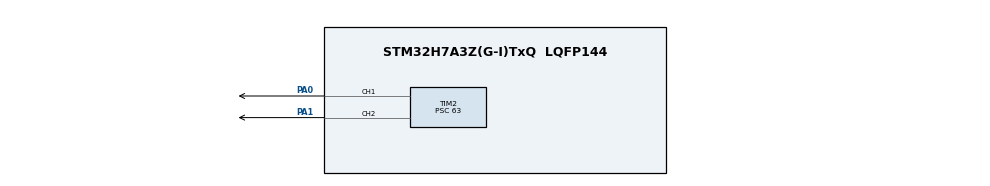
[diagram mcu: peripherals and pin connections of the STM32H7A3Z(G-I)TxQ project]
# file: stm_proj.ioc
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CORTEX_M7.default_mode_Activation=1
FREERTOS.Tasks01=defaultTask,24,128,StartDefaultTask,Default,NULL,Dynamic,NULL,NULL;Task_10ms,32,128,runTask10ms,Default,NULL,Dynamic,NULL,NULL;Task_20ms,24,128,runTask20ms,Default,NULL,Dynamic,NULL,NULL;Task_50ms,24,128,runTask50ms,Default,NULL,Dynamic,NULL,NULL;Initialization,48,128,runInit,Default,NULL,Dynamic,NULL,NULL;Task_1ms,40,128,runTask1ms,Default,NULL,Dynamic,NULL,NULL
FREERTOS.configUSE_NEWLIB_REENTRANT=1
Mcu.Family=STM32H7
Mcu.Name=STM32H7A3Z(G-I)TxQ
Mcu.Package=LQFP144
NUCLEO-H7A3ZI-Q.BUTTON=1
NUCLEO-H7A3ZI-Q.Bsp_Common_DEMO=true
NUCLEO-H7A3ZI-Q.LD1=true
NUCLEO-H7A3ZI-Q.LD2=true
NUCLEO-H7A3ZI-Q.LD3=true
NUCLEO-H7A3ZI-Q.VCP=true
NVIC.EXTI15_10_IRQn=true\:5\:0\:false\:false\:true\:true\:false\:true\:true
NVIC.PriorityGroup=NVIC_PRIORITYGROUP_4
NVIC.TIM1_UP_IRQn=true\:15\:0\:false\:false\:true\:false\:false\:true\:true
NVIC.TimeBase=TIM1_UP_IRQn
NVIC.TimeBaseIP=TIM1
PA0.Signal=S_TIM2_CH1_ETR
PA1.Signal=S_TIM2_CH2
PB0.Signal=S_TIM3_CH3
PB14.Signal=TIM8_CH2N
PC14-OSC32_IN.GPIO_Label=OSC32_IN
PC14-OSC32_IN.Signal=RCC_OSC32_IN
PC15-OSC32_OUT.GPIO_Label=OSC32_OUT
PC15-OSC32_OUT.Signal=RCC_OSC32_OUT
PD8.Signal=USART3_TX
PD9.Signal=USART3_RX
PH0-OSC_IN.GPIO_Label=PH0-MCU
PH0-OSC_IN.Signal=RCC_OSC_IN
PH1-OSC_OUT.GPIO_Label=PH1-MCU
PH1-OSC_OUT.Signal=RCC_OSC_OUT
ProjectManager.HeapSize=0x200
ProjectManager.StackSize=0x400
ProjectManager.TargetToolchain=STM32CubeIDE
RCC.ADCFreq_Value=129000000
RCC.APB1Freq_Value=64000000
RCC.APB2Freq_Value=64000000
RCC.APB3Freq_Value=64000000
RCC.APB4Freq_Value=64000000
RCC.CortexFreq_Value=64000000
RCC.DIVM1=4
RCC.DIVM3=1
RCC.DIVN1=8
RCC.DIVN3=24
RCC.DIVQ1=4
RCC.HCLKFreq_Value=64000000
RCC.HSE_VALUE=8000000
RCC.PLLFRACN=0
RCC.PWR_Regulator_Voltage_Scale=PWR_REGULATOR_VOLTAGE_SCALE0
RCC.SYSCLKFreq_VALUE=64000000
RCC.SYSCLKSource=RCC_SYSCLKSOURCE_PLLCLK
RCC.SupplySource=PWR_DIRECT_SMPS_SUPPLY
RCC.USBCLockSelection=RCC_USBCLKSOURCE_HSI48
RCC.USBFreq_Value=48000000
SH.S_TIM2_CH1_ETR.0=TIM2_CH1,PWM Generation1 CH1
SH.S_TIM2_CH2.0=TIM2_CH2,PWM Generation2 CH2
SH.S_TIM3_CH3.0=TIM3_CH3
TIM2.AutoReloadPreload=TIM_AUTORELOAD_PRELOAD_ENABLE
TIM2.Channel-PWM\ Generation1\ CH1=TIM_CHANNEL_1
TIM2.Channel-PWM\ Generation2\ CH2=TIM_CHANNEL_2
TIM2.Period=999
TIM2.Prescaler=63
TIM3.AutoReloadPreload=TIM_AUTORELOAD_PRELOAD_ENABLE
TIM3.Period=999
TIM3.Prescaler=63
TIM8.AutoReloadPreload=TIM_AUTORELOAD_PRELOAD_ENABLE
TIM8.Period=999
TIM8.Prescaler=63
VP_FREERTOS_VS_CMSIS_V2.Mode=CMSIS_V2
VP_MEMORYMAP_VS_MEMORYMAP.Mode=CurAppReg
VP_NUCLEO-H7A3ZI-Q_VS_BSP_COMMON.Mode=COMMON
VP_SYS_VS_tim1.Mode=TIM1
VP_TIM2_VS_ClockSourceINT.Mode=Internal
VP_TIM3_VS_ClockSourceINT.Mode=Internal
VP_TIM8_VS_ClockSourceINT.Mode=Internal
board=NUCLEO-H7A3ZI-Q

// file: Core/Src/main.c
/* USER CODE BEGIN Header */
/**
  ******************************************************************************
  * @file           : main.c
  * @brief          : Main program body
  ******************************************************************************
  * @attention
  *
  * Copyright (c) 2026 STMicroelectronics.
  * All rights reserved.
  *
  * This software is licensed under terms that can be found in the LICENSE file
  * in the root directory of this software component.
  * If no LICENSE file comes with this software, it is provided AS-IS.
  *
  ******************************************************************************
  */
/* USER CODE END Header */
#include "main.h"
#include "FreeRTOS.h"
#include "cmsis_os2.h"

COM_InitTypeDef BspCOMInit;
__IO uint32_t BspButtonState = BUTTON_RELEASED;

TIM_HandleTypeDef htim2;
TIM_HandleTypeDef htim3;
TIM_HandleTypeDef htim8;

/* Definitions for defaultTask */
osThreadId_t defaultTaskHandle;
const osThreadAttr_t defaultTask_attributes = {
  .name = "defaultTask",
  .stack_size = 128 * 4,
  .priority = (osPriority_t) osPriorityNormal,
};
/* Definitions for Task_10ms */
osThreadId_t Task_10msHandle;
const osThreadAttr_t Task_10ms_attributes = {
  .name = "Task_10ms",
  .stack_size = 128 * 4,
  .priority = (osPriority_t) osPriorityAboveNormal,
};
/* Definitions for Task_20ms */
osThreadId_t Task_20msHandle;
const osThreadAttr_t Task_20ms_attributes = {
  .name = "Task_20ms",
  .stack_size = 128 * 4,
  .priority = (osPriority_t) osPriorityNormal,
};
/* Definitions for Task_50ms */
osThreadId_t Task_50msHandle;
const osThreadAttr_t Task_50ms_attributes = {
  .name = "Task_50ms",
  .stack_size = 128 * 4,
  .priority = (osPriority_t) osPriorityNormal,
};
/* Definitions for Initialization */
osThreadId_t InitializationHandle;
const osThreadAttr_t Initialization_attributes = {
  .name = "Initialization",
  .stack_size = 128 * 4,
  .priority = (osPriority_t) osPriorityRealtime,
};
/* Definitions for Task_1ms */
osThreadId_t Task_1msHandle;
const osThreadAttr_t Task_1ms_attributes = {
  .name = "Task_1ms",
  .stack_size = 128 * 4,
  .priority = (osPriority_t) osPriorityHigh,
};

void SystemClock_Config(void);
static void MPU_Config(void);
static void MX_GPIO_Init(void);
static void MX_TIM2_Init(void);
static void MX_TIM3_Init(void);
static void MX_TIM8_Init(void);
void StartDefaultTask(void *argument);
void runTask10ms(void *argument);
void runTask20ms(void *argument);
void runTask50ms(void *argument);
void runInit(void *argument);
void runTask1ms(void *argument);

int main(void)
{

  /* MPU Configuration--------------------------------------------------------*/
  MPU_Config();

  /* MCU Configuration--------------------------------------------------------*/

  /* Reset of all peripherals, Initializes the Flash interface and the Systick. */
  HAL_Init();

  /* Configure the system clock */
  SystemClock_Config();

  /* Initialize all configured peripherals */
  MX_GPIO_Init();
  MX_TIM2_Init();
  MX_TIM3_Init();
  MX_TIM8_Init();

  /* Init scheduler */
  osKernelInitialize();

  /* Create the thread(s) */
  /* creation of defaultTask */
  defaultTaskHandle = osThreadNew(StartDefaultTask, NULL, &defaultTask_attributes);

  /* creation of Task_10ms */
  Task_10msHandle = osThreadNew(runTask10ms, NULL, &Task_10ms_attributes);

  /* creation of Task_20ms */
  Task_20msHandle = osThreadNew(runTask20ms, NULL, &Task_20ms_attributes);

  /* creation of Task_50ms */
  Task_50msHandle = osThreadNew(runTask50ms, NULL, &Task_50ms_attributes);

  /* creation of Initialization */
  InitializationHandle = osThreadNew(runInit, NULL, &Initialization_attributes);

  /* creation of Task_1ms */
  Task_1msHandle = osThreadNew(runTask1ms, NULL, &Task_1ms_attributes);

  /* Initialize leds */
  BSP_LED_Init(LED_GREEN);
  BSP_LED_Init(LED_YELLOW);
  BSP_LED_Init(LED_RED);

  /* Initialize USER push-button, will be used to trigger an interrupt each time it's pressed.*/
  BSP_PB_Init(BUTTON_USER, BUTTON_MODE_EXTI);

  /* Initialize COM1 port (115200, 8 bits (7-bit data + 1 stop bit), no parity */
  BspCOMInit.BaudRate   = 115200;
  BspCOMInit.WordLength = COM_WORDLENGTH_8B;
  BspCOMInit.StopBits   = COM_STOPBITS_1;
  BspCOMInit.Parity     = COM_PARITY_NONE;
  BspCOMInit.HwFlowCtl  = COM_HWCONTROL_NONE;
  if (BSP_COM_Init(COM1, &BspCOMInit) != BSP_ERROR_NONE)
  {
    Error_Handler();
  }

  /* USER CODE BEGIN BSP */

  /* -- Sample board code to send message over COM1 port ---- */
  printf("Welcome to STM32 world !\n\r");

  /* -- Sample board code to switch on leds ---- */
//  BSP_LED_On(LED_GREEN);
//  BSP_LED_On(LED_YELLOW);
//  BSP_LED_On(LED_RED);

  /* USER CODE END BSP */

  /* Start scheduler */
  osKernelStart();

  /* We should never get here as control is now taken by the scheduler */

  /* Infinite loop */
  /* USER CODE BEGIN WHILE */
  while (1)
  {

    /* -- Sample board code for User push-button in interrupt mode ---- */
//    if (BspButtonState == BUTTON_PRESSED)
//    {
//      /* Update button state */
//      BspButtonState = BUTTON_RELEASED;
//      /* -- Sample board code to toggle leds ---- */
//      BSP_LED_Toggle(LED_GREEN);
//      BSP_LED_Toggle(LED_YELLOW);
//      BSP_LED_Toggle(LED_RED);

      /* ..... Perform your action ..... */
//    }
    /* USER CODE END WHILE */

  }
}

void SystemClock_Config(void)
{
  RCC_OscInitTypeDef RCC_OscInitStruct = {0};
  RCC_ClkInitTypeDef RCC_ClkInitStruct = {0};

  /*AXI clock gating */
  RCC->CKGAENR = 0xE003FFFF;

  /** Supply configuration update enable
  */
  HAL_PWREx_ConfigSupply(PWR_DIRECT_SMPS_SUPPLY);

  /** Configure the main internal regulator output voltage
  */
  __HAL_PWR_VOLTAGESCALING_CONFIG(PWR_REGULATOR_VOLTAGE_SCALE0);

  while(!__HAL_PWR_GET_FLAG(PWR_FLAG_VOSRDY)) {}

  /** Initializes the RCC Oscillators according to the specified parameters
  * in the RCC_OscInitTypeDef structure.
  */
  RCC_OscInitStruct.OscillatorType = RCC_OSCILLATORTYPE_HSI;
  RCC_OscInitStruct.HSIState = RCC_HSI_DIV1;
  RCC_OscInitStruct.HSICalibrationValue = 64;
  RCC_OscInitStruct.PLL.PLLState = RCC_PLL_ON;
  RCC_OscInitStruct.PLL.PLLSource = RCC_PLLSOURCE_HSI;
  RCC_OscInitStruct.PLL.PLLM = 4;
  RCC_OscInitStruct.PLL.PLLN = 8;
  RCC_OscInitStruct.PLL.PLLP = 2;
  RCC_OscInitStruct.PLL.PLLQ = 4;
  RCC_OscInitStruct.PLL.PLLR = 2;
  RCC_OscInitStruct.PLL.PLLRGE = RCC_PLL1VCIRANGE_3;
  RCC_OscInitStruct.PLL.PLLVCOSEL = RCC_PLL1VCOWIDE;
  RCC_OscInitStruct.PLL.PLLFRACN = 0;
  if (HAL_RCC_OscConfig(&RCC_OscInitStruct) != HAL_OK)
  {
    Error_Handler();
  }

  /** Initializes the CPU, AHB and APB buses clocks
  */
  RCC_ClkInitStruct.ClockType = RCC_CLOCKTYPE_HCLK|RCC_CLOCKTYPE_SYSCLK
                              |RCC_CLOCKTYPE_PCLK1|RCC_CLOCKTYPE_PCLK2
                              |RCC_CLOCKTYPE_D3PCLK1|RCC_CLOCKTYPE_D1PCLK1;
  RCC_ClkInitStruct.SYSCLKSource = RCC_SYSCLKSOURCE_PLLCLK;
  RCC_ClkInitStruct.SYSCLKDivider = RCC_SYSCLK_DIV1;
  RCC_ClkInitStruct.AHBCLKDivider = RCC_HCLK_DIV1;
  RCC_ClkInitStruct.APB3CLKDivider = RCC_APB3_DIV1;
  RCC_ClkInitStruct.APB1CLKDivider = RCC_APB1_DIV1;
  RCC_ClkInitStruct.APB2CLKDivider = RCC_APB2_DIV1;
  RCC_ClkInitStruct.APB4CLKDivider = RCC_APB4_DIV1;

  if (HAL_RCC_ClockConfig(&RCC_ClkInitStruct, FLASH_LATENCY_1) != HAL_OK)
  {
    Error_Handler();
  }
}

static void MX_TIM2_Init(void)
{

  TIM_ClockConfigTypeDef sClockSourceConfig = {0};
  TIM_MasterConfigTypeDef sMasterConfig = {0};
  TIM_OC_InitTypeDef sConfigOC = {0};

  htim2.Instance = TIM2;
  htim2.Init.Prescaler = 63;
  htim2.Init.CounterMode = TIM_COUNTERMODE_UP;
  htim2.Init.Period = 999;
  htim2.Init.ClockDivision = TIM_CLOCKDIVISION_DIV1;
  htim2.Init.AutoReloadPreload = TIM_AUTORELOAD_PRELOAD_ENABLE;
  if (HAL_TIM_Base_Init(&htim2) != HAL_OK)
  {
    Error_Handler();
  }
  sClockSourceConfig.ClockSource = TIM_CLOCKSOURCE_INTERNAL;
  if (HAL_TIM_ConfigClockSource(&htim2, &sClockSourceConfig) != HAL_OK)
  {
    Error_Handler();
  }
  if (HAL_TIM_PWM_Init(&htim2) != HAL_OK)
  {
    Error_Handler();
  }
  sMasterConfig.MasterOutputTrigger = TIM_TRGO_RESET;
  sMasterConfig.MasterSlaveMode = TIM_MASTERSLAVEMODE_DISABLE;
  if (HAL_TIMEx_MasterConfigSynchronization(&htim2, &sMasterConfig) != HAL_OK)
  {
    Error_Handler();
  }
  sConfigOC.OCMode = TIM_OCMODE_PWM1;
  sConfigOC.Pulse = 0;
  sConfigOC.OCPolarity = TIM_OCPOLARITY_HIGH;
  sConfigOC.OCFastMode = TIM_OCFAST_DISABLE;
  if (HAL_TIM_PWM_ConfigChannel(&htim2, &sConfigOC, TIM_CHANNEL_1) != HAL_OK)
  {
    Error_Handler();
  }
  if (HAL_TIM_PWM_ConfigChannel(&htim2, &sConfigOC, TIM_CHANNEL_2) != HAL_OK)
  {
    Error_Handler();
  }
  HAL_TIM_MspPostInit(&htim2);

}

static void MX_TIM3_Init(void)
{

  TIM_ClockConfigTypeDef sClockSourceConfig = {0};
  TIM_MasterConfigTypeDef sMasterConfig = {0};

  htim3.Instance = TIM3;
  htim3.Init.Prescaler = 63;
  htim3.Init.CounterMode = TIM_COUNTERMODE_UP;
  htim3.Init.Period = 999;
  htim3.Init.ClockDivision = TIM_CLOCKDIVISION_DIV1;
  htim3.Init.AutoReloadPreload = TIM_AUTORELOAD_PRELOAD_ENABLE;
  if (HAL_TIM_Base_Init(&htim3) != HAL_OK)
  {
    Error_Handler();
  }
  sClockSourceConfig.ClockSource = TIM_CLOCKSOURCE_INTERNAL;
  if (HAL_TIM_ConfigClockSource(&htim3, &sClockSourceConfig) != HAL_OK)
  {
    Error_Handler();
  }
  sMasterConfig.MasterOutputTrigger = TIM_TRGO_RESET;
  sMasterConfig.MasterSlaveMode = TIM_MASTERSLAVEMODE_DISABLE;
  if (HAL_TIMEx_MasterConfigSynchronization(&htim3, &sMasterConfig) != HAL_OK)
  {
    Error_Handler();
  }

}

static void MX_TIM8_Init(void)
{

  TIM_ClockConfigTypeDef sClockSourceConfig = {0};
  TIM_MasterConfigTypeDef sMasterConfig = {0};

  htim8.Instance = TIM8;
  htim8.Init.Prescaler = 63;
  htim8.Init.CounterMode = TIM_COUNTERMODE_UP;
  htim8.Init.Period = 999;
  htim8.Init.ClockDivision = TIM_CLOCKDIVISION_DIV1;
  htim8.Init.RepetitionCounter = 0;
  htim8.Init.AutoReloadPreload = TIM_AUTORELOAD_PRELOAD_ENABLE;
  if (HAL_TIM_Base_Init(&htim8) != HAL_OK)
  {
    Error_Handler();
  }
  sClockSourceConfig.ClockSource = TIM_CLOCKSOURCE_INTERNAL;
  if (HAL_TIM_ConfigClockSource(&htim8, &sClockSourceConfig) != HAL_OK)
  {
    Error_Handler();
  }
  sMasterConfig.MasterOutputTrigger = TIM_TRGO_RESET;
  sMasterConfig.MasterOutputTrigger2 = TIM_TRGO2_RESET;
  sMasterConfig.MasterSlaveMode = TIM_MASTERSLAVEMODE_DISABLE;
  if (HAL_TIMEx_MasterConfigSynchronization(&htim8, &sMasterConfig) != HAL_OK)
  {
    Error_Handler();
  }

}

static void MX_GPIO_Init(void)
{

  /* GPIO Ports Clock Enable */
  __HAL_RCC_GPIOC_CLK_ENABLE();
  __HAL_RCC_GPIOH_CLK_ENABLE();
  __HAL_RCC_GPIOA_CLK_ENABLE();
  __HAL_RCC_GPIOB_CLK_ENABLE();

}

void StartDefaultTask(void *argument)
{
  /* USER CODE BEGIN 5 */
	  HAL_TIM_PWM_Start(&htim3, TIM_CHANNEL_3);

	  // FORCE 100%
	  __HAL_TIM_SET_COMPARE(&htim3, TIM_CHANNEL_3, 999);
	// TIM3
//	HAL_GPIO_WritePin(GPIOB, GPIO_PIN_0, GPIO_PIN_SET);
    for(;;)
    {
      osDelay(1000);
    }
  /* USER CODE END 5 */
}

void runTask10ms(void *argument)
{
  /* USER CODE BEGIN runTask10ms */
  /* Infinite loop */
  for(;;)
  {
	  cyclic_task_10ms();
    osDelay(10);
  }
  /* USER CODE END runTask10ms */
}

void runTask20ms(void *argument)
{
  /* USER CODE BEGIN runTask20ms */
  /* Infinite loop */
  for(;;)
  {
	  cyclic_task_20ms();
    osDelay(20);
  }
  /* USER CODE END runTask20ms */
}

void runTask50ms(void *argument)
{
  /* USER CODE BEGIN runTask50ms */
  /* Infinite loop */
  for(;;)
  {
	  cyclic_task_50ms();
    osDelay(50);
  }
  /* USER CODE END runTask50ms */
}

void runInit(void *argument)
{
  /* USER CODE BEGIN runInit */
  /* Infinite loop */
  for(;;)
  {
	  init();
    osDelay(1);
  }
  /* USER CODE END runInit */
}

void runTask1ms(void *argument)
{
  /* USER CODE BEGIN runTask1ms */
  /* Infinite loop */
  for(;;)
  {
	  cyclic_task_1ms();
    osDelay(1);
  }
  /* USER CODE END runTask1ms */
}

 /* MPU Configuration */

void MPU_Config(void)
{
  MPU_Region_InitTypeDef MPU_InitStruct = {0};

  /* Disables the MPU */
  HAL_MPU_Disable();

  /** Initializes and configures the Region and the memory to be protected
  */
  MPU_InitStruct.Enable = MPU_REGION_ENABLE;
  MPU_InitStruct.Number = MPU_REGION_NUMBER0;
  MPU_InitStruct.BaseAddress = 0x0;
  MPU_InitStruct.Size = MPU_REGION_SIZE_4GB;
  MPU_InitStruct.SubRegionDisable = 0x87;
  MPU_InitStruct.TypeExtField = MPU_TEX_LEVEL0;
  MPU_InitStruct.AccessPermission = MPU_REGION_NO_ACCESS;
  MPU_InitStruct.DisableExec = MPU_INSTRUCTION_ACCESS_DISABLE;
  MPU_InitStruct.IsShareable = MPU_ACCESS_SHAREABLE;
  MPU_InitStruct.IsCacheable = MPU_ACCESS_NOT_CACHEABLE;
  MPU_InitStruct.IsBufferable = MPU_ACCESS_NOT_BUFFERABLE;

  HAL_MPU_ConfigRegion(&MPU_InitStruct);
  /* Enables the MPU */
  HAL_MPU_Enable(MPU_PRIVILEGED_DEFAULT);

}

void HAL_TIM_PeriodElapsedCallback(TIM_HandleTypeDef *htim)
{
  if (htim->Instance == TIM1)
  {
    HAL_IncTick();
  }
}

/**
  * @brief BSP Push Button callback
  * @param Button Specifies the pressed button
  * @retval None
  */
void BSP_PB_Callback(Button_TypeDef Button)
{
  if (Button == BUTTON_USER)
  {
    BspButtonState = BUTTON_PRESSED;
  }
}

void Error_Handler(void)
{
  __disable_irq();
  while (1)
  {
  }
}
